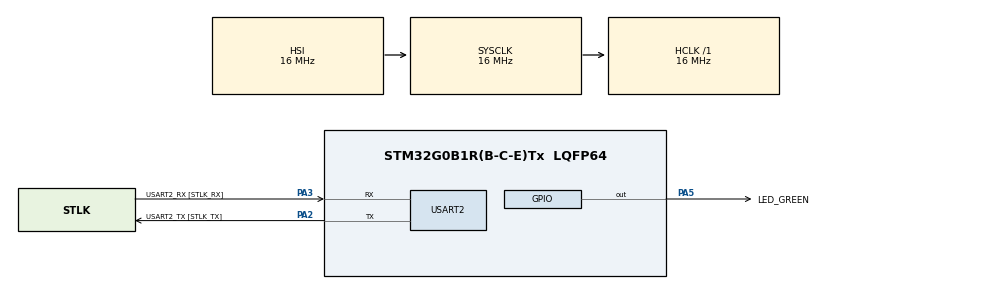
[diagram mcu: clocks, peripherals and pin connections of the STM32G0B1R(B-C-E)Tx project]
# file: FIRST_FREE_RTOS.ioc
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FREERTOS.Tasks01=defaultTask,24,128,StartDefaultTask,Default,NULL,Dynamic,NULL,NULL
FREERTOS.configUSE_NEWLIB_REENTRANT=1
Mcu.Family=STM32G0
Mcu.Name=STM32G0B1R(B-C-E)Tx
Mcu.Package=LQFP64
NVIC.TIM1_BRK_UP_TRG_COM_IRQn=true\:3\:0\:false\:false\:true\:false\:false\:true\:true
NVIC.TimeBase=TIM1_BRK_UP_TRG_COM_IRQn
NVIC.TimeBaseIP=TIM1
PA13.GPIO_Label=TMS
PA13.Mode=Serial_Wire
PA13.Signal=SYS_SWDIO
PA14-BOOT0.GPIO_Label=TCK
PA14-BOOT0.Mode=Serial_Wire
PA14-BOOT0.Signal=SYS_SWCLK
PA2.GPIO_Label=USART2_TX [STLK_TX]
PA2.Mode=Asynchronous
PA2.Signal=USART2_TX
PA3.GPIO_Label=USART2_RX [STLK_RX]
PA3.Mode=Asynchronous
PA3.Signal=USART2_RX
PA5.GPIO_Label=LED_GREEN
PA5.GPIO_Speed=GPIO_SPEED_FREQ_HIGH
PA5.Signal=GPIO_Output
PC13.Mode=SYS_WakeUp1
PC13.Signal=SYS_WKUP2
PC14-OSC32_IN\ (PC14).Mode=LSE-External-Oscillator
PC14-OSC32_IN\ (PC14).Signal=RCC_OSC32_IN
PC15-OSC32_OUT\ (PC15).Mode=LSE-External-Oscillator
PC15-OSC32_OUT\ (PC15).Signal=RCC_OSC32_OUT
PF0-OSC_IN\ (PF0).GPIO_Label=MCO
PF0-OSC_IN\ (PF0).Mode=HSE-External-Clock-Source
PF0-OSC_IN\ (PF0).Signal=RCC_OSC_IN
ProjectManager.HeapSize=0x200
ProjectManager.StackSize=0x400
ProjectManager.TargetToolchain=STM32CubeIDE
RCC.AHBFreq_Value=16000000
RCC.CortexFreq_Value=16000000
RCC.EXTERNAL_CLOCK_VALUE=12288000
RCC.HCLKFreq_Value=16000000
RCC.HSE_VALUE=8000000
RCC.HSI48_VALUE=48000000
RCC.HSI_VALUE=16000000
RCC.SYSCLKFreq_VALUE=16000000
RCC.USBFreq_Value=48000000
RCC.VCOOutputFreq_Value=128000000
USART2.VirtualMode-Asynchronous=VM_ASYNC
VP_FREERTOS_VS_CMSIS_V2.Mode=CMSIS_V2
VP_SYS_VS_tim1.Mode=TIM1
board=NUCLEO-G0B1RE

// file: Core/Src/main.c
/* USER CODE BEGIN Header */
/**
  ******************************************************************************
  * @file           : main.c
  * @brief          : Main program body
  ******************************************************************************
  * @attention
  *
  * Copyright (c) 2024 STMicroelectronics.
  * All rights reserved.
  *
  * This software is licensed under terms that can be found in the LICENSE file
  * in the root directory of this software component.
  * If no LICENSE file comes with this software, it is provided AS-IS.
  *
  ******************************************************************************
  */
/* USER CODE END Header */
#include "main.h"
#include "cmsis_os.h"

/* USER CODE BEGIN Includes */
#include "stdio.h"
#include "queue.h"
#include <string.h>
/* USER CODE END Includes */

UART_HandleTypeDef huart2;

/* Definitions for defaultTask */
/*
osThreadId_t defaultTaskHandle;
const osThreadAttr_t defaultTask_attributes = {
  .name = "defaultTask",
  .priority = (osPriority_t) osPriorityNormal,
  .stack_size = 128 * 4
};
*/

void SystemClock_Config(void);
static void MX_GPIO_Init(void);
static void MX_USART2_UART_Init(void);
int __io_putchar(int ch);

/* USER CODE BEGIN PFP */

//void StartDefaultTask(void *argument);
void vBlueLedControlerTask(void * pvParameters);
void vRedLedControlerTask(void * pvParameters);
void vGreenLedControlerTask(void * pvParameters);

void vReceiveTask(void * pvParameters);
void vSenderTask(void * pvParameters);

/* USER CODE END PFP */

/* USER CODE BEGIN 0 */

// Define some constants
typedef enum {
	humidity_sensor = 65,
	pressure_sensor = 66,
	light_sensor = 67
} DataSource_t;

// Define a datatype
typedef struct {
	char name[15];
	char age[4];
	char length[4];
} Person_t;

// Define structure type to be passed to the queue
typedef struct {
	uint8_t ucValue[13];
	DataSource_t sDataSource;
	Person_t supervisor;
} Data_t;

static const Person_t teachers[3] = {
		{"John Kumah", "25", "174"},
		{"Kyei Mensah", "30", "180"}
};

static const Data_t xStructsToSend[3] = {
		{"firt name ", humidity_sensor, teachers[0]},	// used by humidity sensor
		{"second name ", pressure_sensor, teachers[1]}	// used by pressure sensor
};

TaskHandle_t humTaskHandle, pressTaskHandle, receiverTaskHandle;

// Declare queue handle for passing dadta across tasks
QueueHandle_t xQueue;

/* USER CODE END 0 */

// HAL_UART_Transmit(UART_HandleTypeDef *huart, const uint8_t *pData, uint16_t Size, uint32_t Timeout)

typedef uint32_t TaskProfiler;

TaskProfiler BlueTaskProfiler;
TaskProfiler RedTaskProfiler;
TaskProfiler GreenTaskProfiler;

int main(void)
{

  /* MCU Configuration--------------------------------------------------------*/

  /* Reset of all peripherals, Initializes the Flash interface and the Systick. */
  HAL_Init();

  /* Configure the system clock */
  SystemClock_Config();

  /* Initialize all configured peripherals */
  MX_GPIO_Init();
  MX_USART2_UART_Init();
  /* USER CODE BEGIN 2 */

  // create queue to hold a maximum of 3 structures
  xQueue = xQueueCreate(3, sizeof(Data_t));

  /* USER CODE END 2 */

  /* Init scheduler */
 // osKernelInitialize();

  /* Create the thread(s) */
  /* creation of defaultTask */
  //defaultTaskHandle = osThreadNew(StartDefaultTask, NULL, &defaultTask_attributes);

  /* Start scheduler */
  osKernelStart();

  /* We should never get here as control is now taken by the scheduler */
  /* Infinite loop */
  /* USER CODE BEGIN WHILE */

  // create task

  /*
  xTaskCreate(vBlueLedControlerTask,
		  "Ble Led controller",
		  100,
		  NULL,
		  1,
		  NULL);

  xTaskCreate(vRedLedControlerTask,
		  "Red Led controller",
		  100,
		  NULL,
		  1,
		  NULL);

  xTaskCreate(vGreenLedControlerTask,
		  "Green Led controller",
		  100,
		  NULL,
		  1,
		  NULL); */

// The task below were created for learning queue management
  xTaskCreate(vReceiveTask,
		  "Receive Task",
		  100,
		  NULL,
		  1,
		  &receiverTaskHandle);

  xTaskCreate(vSenderTask,
		  "Humidity SendorTask",
		  100,
		  (void *)&(xStructsToSend[0]),
		  1,
		  &humTaskHandle);

  xTaskCreate(vSenderTask,
  		  "Humidity SendorTask",
  		  100,
  		  (void *)&(xStructsToSend[1]),
  		  1,
  		  &pressTaskHandle);

  vTaskStartScheduler();	// start schedule

  //int ch[3] = {'H','e','l'};
  while (1)
  {

	  //HAL_UART_Transmit(&huart2, (uint8_t *)ch, sizeof(ch), 0xFFFF);
	  //printf("Hello from stm32\n\r");
    /* USER CODE END WHILE */

  }
}

void SystemClock_Config(void)
{
  RCC_OscInitTypeDef RCC_OscInitStruct = {0};
  RCC_ClkInitTypeDef RCC_ClkInitStruct = {0};

  /** Configure the main internal regulator output voltage
  */
  HAL_PWREx_ControlVoltageScaling(PWR_REGULATOR_VOLTAGE_SCALE1);

  /** Initializes the RCC Oscillators according to the specified parameters
  * in the RCC_OscInitTypeDef structure.
  */
  RCC_OscInitStruct.OscillatorType = RCC_OSCILLATORTYPE_HSI;
  RCC_OscInitStruct.HSIState = RCC_HSI_ON;
  RCC_OscInitStruct.HSIDiv = RCC_HSI_DIV1;
  RCC_OscInitStruct.HSICalibrationValue = RCC_HSICALIBRATION_DEFAULT;
  RCC_OscInitStruct.PLL.PLLState = RCC_PLL_NONE;
  if (HAL_RCC_OscConfig(&RCC_OscInitStruct) != HAL_OK)
  {
    Error_Handler();
  }

  /** Initializes the CPU, AHB and APB buses clocks
  */
  RCC_ClkInitStruct.ClockType = RCC_CLOCKTYPE_HCLK|RCC_CLOCKTYPE_SYSCLK
                              |RCC_CLOCKTYPE_PCLK1;
  RCC_ClkInitStruct.SYSCLKSource = RCC_SYSCLKSOURCE_HSI;
  RCC_ClkInitStruct.AHBCLKDivider = RCC_SYSCLK_DIV1;
  RCC_ClkInitStruct.APB1CLKDivider = RCC_HCLK_DIV1;

  if (HAL_RCC_ClockConfig(&RCC_ClkInitStruct, FLASH_LATENCY_0) != HAL_OK)
  {
    Error_Handler();
  }
}

static void MX_USART2_UART_Init(void)
{

  huart2.Instance = USART2;
  huart2.Init.BaudRate = 115200;
  huart2.Init.WordLength = UART_WORDLENGTH_8B;
  huart2.Init.StopBits = UART_STOPBITS_1;
  huart2.Init.Parity = UART_PARITY_NONE;
  huart2.Init.Mode = UART_MODE_TX_RX;
  huart2.Init.HwFlowCtl = UART_HWCONTROL_NONE;
  huart2.Init.OverSampling = UART_OVERSAMPLING_16;
  huart2.Init.OneBitSampling = UART_ONE_BIT_SAMPLE_DISABLE;
  huart2.Init.ClockPrescaler = UART_PRESCALER_DIV1;
  huart2.AdvancedInit.AdvFeatureInit = UART_ADVFEATURE_NO_INIT;
  if (HAL_UART_Init(&huart2) != HAL_OK)
  {
    Error_Handler();
  }
  if (HAL_UARTEx_SetTxFifoThreshold(&huart2, UART_TXFIFO_THRESHOLD_1_8) != HAL_OK)
  {
    Error_Handler();
  }
  if (HAL_UARTEx_SetRxFifoThreshold(&huart2, UART_RXFIFO_THRESHOLD_1_8) != HAL_OK)
  {
    Error_Handler();
  }
  if (HAL_UARTEx_DisableFifoMode(&huart2) != HAL_OK)
  {
    Error_Handler();
  }

}

static void MX_GPIO_Init(void)
{
  GPIO_InitTypeDef GPIO_InitStruct = {0};

  /* GPIO Ports Clock Enable */
  __HAL_RCC_GPIOC_CLK_ENABLE();
  __HAL_RCC_GPIOF_CLK_ENABLE();
  __HAL_RCC_GPIOA_CLK_ENABLE();

  /*Configure GPIO pin Output Level */
  HAL_GPIO_WritePin(LED_GREEN_GPIO_Port, LED_GREEN_Pin, GPIO_PIN_RESET);

  /*Configure GPIO pin : LED_GREEN_Pin */
  GPIO_InitStruct.Pin = LED_GREEN_Pin;
  GPIO_InitStruct.Mode = GPIO_MODE_OUTPUT_PP;
  GPIO_InitStruct.Pull = GPIO_NOPULL;
  GPIO_InitStruct.Speed = GPIO_SPEED_FREQ_HIGH;
  HAL_GPIO_Init(LED_GREEN_GPIO_Port, &GPIO_InitStruct);

}

/* USER CODE BEGIN 4 */

// repurpose printf to transmit uart
int __io_putchar(int ch){
	HAL_UART_Transmit(&huart2, (uint8_t *)&ch, sizeof(ch), 0xFFFF);
	return ch;
}

// craete task

// craete task
void vBlueLedControlerTask(void * pvParameters)
{
	while(1){
		BlueTaskProfiler++;
	}
}

void vRedLedControlerTask(void * pvParameters)
{
	while(1){
		//printf("vRedLedControllerTask Red...\n\r");
		RedTaskProfiler++;
	}
}

void vGreenLedControlerTask(void * pvParameters)
{
	while(1){
		//printf("vGreenLedControllerTask Green...\n\r");
		GreenTaskProfiler++;
	}
}

void vSenderTask(void * pvParameters){
	BaseType_t qStatus;

	const TickType_t wait_time = pdMS_TO_TICKS(200);

	while(1){
		RedTaskProfiler++;
		//printf("vBleLedControllerTask blue...\n\r");

		// send value to queue
		qStatus = xQueueSend(xQueue, pvParameters, wait_time);
		if(qStatus != pdPASS){
			// do something
		}
		//for(int i=0; i<10000; i++);
	}
}

void vReceiveTask(void * pvParameters)
{
	Data_t xReceivedStructure;
	BaseType_t qStatus;
	//const char* msg = "Mercy me";

	while(1){
		//printf("vBleLedControllerTask blue...\n\r");
		BlueTaskProfiler++;

		qStatus = xQueueReceive(xQueue, &xReceivedStructure, 0);
		if(qStatus == pdPASS){

			   //HAL_UART_Transmit(&huart2, (uint8_t *)msg, strlen(msg), HAL_MAX_DELAY);
			if(xReceivedStructure.sDataSource == humidity_sensor){
				   HAL_UART_Transmit(&huart2, (uint8_t *)(xReceivedStructure.ucValue), sizeof(xReceivedStructure) * 2, HAL_MAX_DELAY);
				  // HAL_UART_Transmit(&huart2, (uint8_t *)(xReceivedStructure.sDataSource), 8, HAL_MAX_DELAY);
			}

			if(xReceivedStructure.sDataSource == pressure_sensor){
						   HAL_UART_Transmit(&huart2, (uint8_t *)(xReceivedStructure.ucValue), sizeof(xReceivedStructure), HAL_MAX_DELAY);
						   //HAL_UART_Transmit(&huart2, (uint8_t *)(xReceivedStructure.sDataSource), 8, HAL_MAX_DELAY);
					}

		}

	}
}

/* USER CODE END 4 */

void HAL_TIM_PeriodElapsedCallback(TIM_HandleTypeDef *htim)
{
  if (htim->Instance == TIM1) {
    HAL_IncTick();
  }
}

void Error_Handler(void)
{
  __disable_irq();
  while (1)
  {
  }
}
